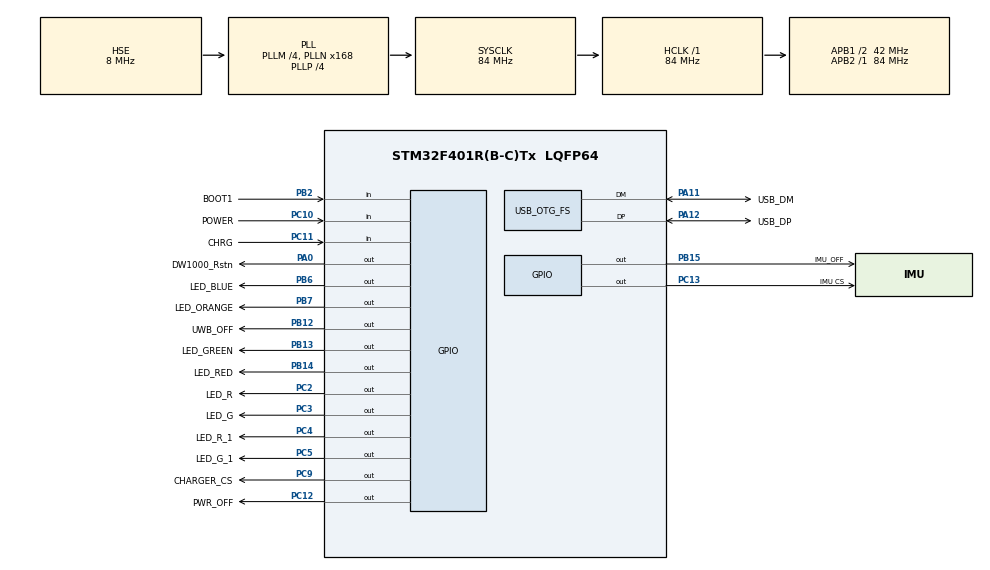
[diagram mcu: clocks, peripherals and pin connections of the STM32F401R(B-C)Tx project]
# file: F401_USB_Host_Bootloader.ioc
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Mcu.Family=STM32F4
Mcu.Name=STM32F401R(B-C)Tx
Mcu.Package=LQFP64
NVIC.OTG_FS_IRQn=true\:0\:0\:false\:false\:true\:false
NVIC.PriorityGroup=NVIC_PRIORITYGROUP_4
PA0-WKUP.GPIO_Label=DW1000_Rstn
PA0-WKUP.GPIO_Speed=GPIO_SPEED_FREQ_MEDIUM
PA0-WKUP.Signal=GPIO_Output
PA11.GPIO_Label=USB_DM
PA11.Mode=Host_Only
PA11.Signal=USB_OTG_FS_DM
PA12.GPIO_Label=USB_DP
PA12.Mode=Host_Only
PA12.Signal=USB_OTG_FS_DP
PA13.Mode=JTAG_5_pins
PA13.Signal=SYS_JTMS-SWDIO
PA14.Mode=JTAG_5_pins
PA14.Signal=SYS_JTCK-SWCLK
PA15.Mode=JTAG_5_pins
PA15.Signal=SYS_JTDI
PB12.GPIO_Label=UWB_OFF
PB12.GPIO_Speed=GPIO_SPEED_FREQ_MEDIUM
PB12.Signal=GPIO_Output
PB13.GPIO_Label=LED_GREEN
PB13.GPIO_Speed=GPIO_SPEED_FREQ_MEDIUM
PB13.Signal=GPIO_Output
PB14.GPIO_Label=LED_RED
PB14.GPIO_Speed=GPIO_SPEED_FREQ_MEDIUM
PB14.Signal=GPIO_Output
PB15.GPIO_Label=IMU_OFF
PB15.GPIO_Speed=GPIO_SPEED_FREQ_MEDIUM
PB15.Signal=GPIO_Output
PB2.GPIO_Label=BOOT1
PB2.Signal=GPIO_Input
PB3.Mode=JTAG_5_pins
PB3.Signal=SYS_JTDO-SWO
PB4.Mode=JTAG_5_pins
PB4.Signal=SYS_JTRST
PB6.GPIO_Label=LED_BLUE
PB6.GPIO_Speed=GPIO_SPEED_FREQ_MEDIUM
PB6.Signal=GPIO_Output
PB7.GPIO_Label=LED_ORANGE
PB7.GPIO_Speed=GPIO_SPEED_FREQ_MEDIUM
PB7.Signal=GPIO_Output
PC10.GPIO_Label=POWER
PC10.Signal=GPIO_Input
PC11.GPIO_Label=CHRG
PC11.Signal=GPIO_Input
PC12.GPIO_Label=PWR_OFF
PC12.GPIO_Speed=GPIO_SPEED_FREQ_MEDIUM
PC12.Signal=GPIO_Output
PC13-ANTI_TAMP.GPIO_Label=IMU CS
PC13-ANTI_TAMP.GPIO_Speed=GPIO_SPEED_FREQ_LOW
PC13-ANTI_TAMP.Signal=GPIO_Output
PC14-OSC32_IN.GPIO_Label=OSC32_IN
PC14-OSC32_IN.Mode=LSE-External-Oscillator
PC14-OSC32_IN.Signal=RCC_OSC32_IN
PC15-OSC32_OUT.GPIO_Label=OSC32_OUT
PC15-OSC32_OUT.Mode=LSE-External-Oscillator
PC15-OSC32_OUT.Signal=RCC_OSC32_OUT
PC2.GPIO_Label=LED_R
PC2.GPIO_Speed=GPIO_SPEED_FREQ_MEDIUM
PC2.Signal=GPIO_Output
PC3.GPIO_Label=LED_G
PC3.GPIO_Speed=GPIO_SPEED_FREQ_MEDIUM
PC3.Signal=GPIO_Output
PC4.GPIO_Label=LED_R_1
PC4.GPIO_Speed=GPIO_SPEED_FREQ_MEDIUM
PC4.Signal=GPIO_Output
PC5.GPIO_Label=LED_G_1
PC5.GPIO_Speed=GPIO_SPEED_FREQ_MEDIUM
PC5.Signal=GPIO_Output
PC9.GPIO_Label=CHARGER_CS
PC9.GPIO_Speed=GPIO_SPEED_FREQ_MEDIUM
PC9.Signal=GPIO_Output
PH0\ -\ OSC_IN.GPIO_Label=OSC_IN
PH0\ -\ OSC_IN.Mode=HSE-External-Oscillator
PH0\ -\ OSC_IN.Signal=RCC_OSC_IN
PH1\ -\ OSC_OUT.GPIO_Label=OSC_OUT
PH1\ -\ OSC_OUT.Mode=HSE-External-Oscillator
PH1\ -\ OSC_OUT.Signal=RCC_OSC_OUT
ProjectManager.HeapSize=0x1000
ProjectManager.StackSize=0x1000
ProjectManager.TargetToolchain=MDK-ARM V5
RCC.48MHZClocksFreq_Value=48000000
RCC.AHBFreq_Value=84000000
RCC.APB1CLKDivider=RCC_HCLK_DIV2
RCC.APB1Freq_Value=42000000
RCC.APB1TimFreq_Value=84000000
RCC.APB2Freq_Value=84000000
RCC.APB2TimFreq_Value=84000000
RCC.CortexFreq_Value=84000000
RCC.HCLKFreq_Value=84000000
RCC.HSE_VALUE=8000000
RCC.HSI_VALUE=16000000
RCC.PLLM=4
RCC.PLLN=168
RCC.PLLP=RCC_PLLP_DIV4
RCC.PLLQ=7
RCC.SYSCLKFreq_VALUE=84000000
RCC.SYSCLKSource=RCC_SYSCLKSOURCE_PLLCLK
RCC.VCOOutputFreq_Value=336000000
USB_HOST.USBH_HandleTypeDef=hUsbHostFS
USB_HOST.VirtualModeFS=Msc
USB_OTG_FS.VirtualMode=Host_Only
USB_OTG_FS.phy_itface=HCD_PHY_EMBEDDED
VP_FATFS_VS_USB.Mode=USB
VP_USB_HOST_VS_USB_HOST_MSC_FS.Mode=MSC_FS
board=F401_USB_Host_Bootloader

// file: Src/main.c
/**
  ******************************************************************************
  * @file           : main.c
  * @brief          : Main program body
  ******************************************************************************
  * This notice applies to any and all portions of this file
  * that are not between comment pairs USER CODE BEGIN and
  * USER CODE END. Other portions of this file, whether
  * inserted by the user or by software development tools
  * are owned by their respective copyright owners.
  *
  * Copyright (c) 2018 STMicroelectronics International N.V.
  * All rights reserved.
  *
  * Redistribution and use in source and binary forms, with or without
  * modification, are permitted, provided that the following conditions are met:
  *
  * 1. Redistribution of source code must retain the above copyright notice,
  *    this list of conditions and the following disclaimer.
  * 2. Redistributions in binary form must reproduce the above copyright notice,
  *    this list of conditions and the following disclaimer in the documentation
  *    and/or other materials provided with the distribution.
  * 3. Neither the name of STMicroelectronics nor the names of other
  *    contributors to this software may be used to endorse or promote products
  *    derived from this software without specific written permission.
  * 4. This software, including modifications and/or derivative works of this
  *    software, must execute solely and exclusively on microcontroller or
  *    microprocessor devices manufactured by or for STMicroelectronics.
  * 5. Redistribution and use of this software other than as permitted under
  *    this license is void and will automatically terminate your rights under
  *    this license.
  *
  * THIS SOFTWARE IS PROVIDED BY STMICROELECTRONICS AND CONTRIBUTORS "AS IS"
  * AND ANY EXPRESS, IMPLIED OR STATUTORY WARRANTIES, INCLUDING, BUT NOT
  * LIMITED TO, THE IMPLIED WARRANTIES OF MERCHANTABILITY, FITNESS FOR A
  * PARTICULAR PURPOSE AND NON-INFRINGEMENT OF THIRD PARTY INTELLECTUAL PROPERTY
  * RIGHTS ARE DISCLAIMED TO THE FULLEST EXTENT PERMITTED BY LAW. IN NO EVENT
  * SHALL STMICROELECTRONICS OR CONTRIBUTORS BE LIABLE FOR ANY DIRECT, INDIRECT,
  * INCIDENTAL, SPECIAL, EXEMPLARY, OR CONSEQUENTIAL DAMAGES (INCLUDING, BUT NOT
  * LIMITED TO, PROCUREMENT OF SUBSTITUTE GOODS OR SERVICES; LOSS OF USE, DATA,
  * OR PROFITS; OR BUSINESS INTERRUPTION) HOWEVER CAUSED AND ON ANY THEORY OF
  * LIABILITY, WHETHER IN CONTRACT, STRICT LIABILITY, OR TORT (INCLUDING
  * NEGLIGENCE OR OTHERWISE) ARISING IN ANY WAY OUT OF THE USE OF THIS SOFTWARE,
  * EVEN IF ADVISED OF THE POSSIBILITY OF SUCH DAMAGE.
  *
  ******************************************************************************
  */
#include "main.h"
#include "stm32f4xx_hal.h"
#include "fatfs.h"
#include "usb_host.h"

/* USER CODE BEGIN Includes */

#include "driver.h"

/* USER CODE END Includes */

/* USER CODE BEGIN PV */
/* Private variables ---------------------------------------------------------*/

/* USER CODE END PV */

void SystemClock_Config(void);
static void MX_GPIO_Init(void);
void MX_USB_HOST_Process(void);

/* USER CODE BEGIN PFP */
/* Private function prototypes -----------------------------------------------*/

/* USER CODE END PFP */

int main(void)
{

    /* MCU Configuration----------------------------------------------------------*/

    /* Reset of all peripherals, Initializes the Flash interface and the Systick. */
    HAL_Init();

    /* Configure the system clock */
    SystemClock_Config();

    /* Initialize all configured peripherals */
    MX_GPIO_Init();
    MX_USB_HOST_Init();
    MX_FATFS_Init();
    /* USER CODE BEGIN 2 */

    MX_USB_HOST_Process();
    App_Init();

    /* USER CODE END 2 */

    /* Infinite loop */
    /* USER CODE BEGIN WHILE */
    while (1)
    {
        App_Process();

        /* USER CODE END WHILE */
        MX_USB_HOST_Process();

    }

}

void SystemClock_Config(void)
{

    RCC_OscInitTypeDef RCC_OscInitStruct;
    RCC_ClkInitTypeDef RCC_ClkInitStruct;

    /**Configure the main internal regulator output voltage
    */
    __HAL_RCC_PWR_CLK_ENABLE();

    __HAL_PWR_VOLTAGESCALING_CONFIG(PWR_REGULATOR_VOLTAGE_SCALE2);

    /**Initializes the CPU, AHB and APB busses clocks
    */
    RCC_OscInitStruct.OscillatorType = RCC_OSCILLATORTYPE_HSE;
    RCC_OscInitStruct.HSEState = RCC_HSE_ON;
    RCC_OscInitStruct.PLL.PLLState = RCC_PLL_ON;
    RCC_OscInitStruct.PLL.PLLSource = RCC_PLLSOURCE_HSE;
    RCC_OscInitStruct.PLL.PLLM = 4;
    RCC_OscInitStruct.PLL.PLLN = 168;
    RCC_OscInitStruct.PLL.PLLP = RCC_PLLP_DIV4;
    RCC_OscInitStruct.PLL.PLLQ = 7;
    if (HAL_RCC_OscConfig(&RCC_OscInitStruct) != HAL_OK)
    {
        _Error_Handler(__FILE__, __LINE__);
    }

    /**Initializes the CPU, AHB and APB busses clocks
    */
    RCC_ClkInitStruct.ClockType = RCC_CLOCKTYPE_HCLK|RCC_CLOCKTYPE_SYSCLK
                                  |RCC_CLOCKTYPE_PCLK1|RCC_CLOCKTYPE_PCLK2;
    RCC_ClkInitStruct.SYSCLKSource = RCC_SYSCLKSOURCE_PLLCLK;
    RCC_ClkInitStruct.AHBCLKDivider = RCC_SYSCLK_DIV1;
    RCC_ClkInitStruct.APB1CLKDivider = RCC_HCLK_DIV2;
    RCC_ClkInitStruct.APB2CLKDivider = RCC_HCLK_DIV1;

    if (HAL_RCC_ClockConfig(&RCC_ClkInitStruct, FLASH_LATENCY_2) != HAL_OK)
    {
        _Error_Handler(__FILE__, __LINE__);
    }

    /**Configure the Systick interrupt time
    */
    HAL_SYSTICK_Config(HAL_RCC_GetHCLKFreq()/1000);

    /**Configure the Systick
    */
    HAL_SYSTICK_CLKSourceConfig(SYSTICK_CLKSOURCE_HCLK);

    /* SysTick_IRQn interrupt configuration */
    HAL_NVIC_SetPriority(SysTick_IRQn, 0, 0);
}

/** Configure pins as
        * Analog
        * Input
        * Output
        * EVENT_OUT
        * EXTI
*/
static void MX_GPIO_Init(void)
{

    GPIO_InitTypeDef GPIO_InitStruct;

    /* GPIO Ports Clock Enable */
    __HAL_RCC_GPIOC_CLK_ENABLE();
    __HAL_RCC_GPIOH_CLK_ENABLE();
    __HAL_RCC_GPIOA_CLK_ENABLE();
    __HAL_RCC_GPIOB_CLK_ENABLE();

    /*Configure GPIO pin Output Level */
    HAL_GPIO_WritePin(GPIOC, IMU_CS_Pin|LED_R_Pin|LED_G_Pin|LED_R_1_Pin
                      |LED_G_1_Pin|CHARGER_CS_Pin|PWR_OFF_Pin, GPIO_PIN_RESET);

    /*Configure GPIO pin Output Level */
    HAL_GPIO_WritePin(DW1000_Rstn_GPIO_Port, DW1000_Rstn_Pin, GPIO_PIN_RESET);

    /*Configure GPIO pin Output Level */
    HAL_GPIO_WritePin(GPIOB, UWB_OFF_Pin|LED_GREEN_Pin|LED_RED_Pin|IMU_OFF_Pin
                      |LED_BLUE_Pin|LED_ORANGE_Pin, GPIO_PIN_RESET);

    /*Configure GPIO pin : IMU_CS_Pin */
    GPIO_InitStruct.Pin = IMU_CS_Pin;
    GPIO_InitStruct.Mode = GPIO_MODE_OUTPUT_PP;
    GPIO_InitStruct.Pull = GPIO_NOPULL;
    GPIO_InitStruct.Speed = GPIO_SPEED_FREQ_LOW;
    HAL_GPIO_Init(IMU_CS_GPIO_Port, &GPIO_InitStruct);

    /*Configure GPIO pins : LED_R_Pin LED_G_Pin LED_R_1_Pin LED_G_1_Pin
                             CHARGER_CS_Pin PWR_OFF_Pin */
    GPIO_InitStruct.Pin = LED_R_Pin|LED_G_Pin|LED_R_1_Pin|LED_G_1_Pin
                          |CHARGER_CS_Pin|PWR_OFF_Pin;
    GPIO_InitStruct.Mode = GPIO_MODE_OUTPUT_PP;
    GPIO_InitStruct.Pull = GPIO_NOPULL;
    GPIO_InitStruct.Speed = GPIO_SPEED_FREQ_MEDIUM;
    HAL_GPIO_Init(GPIOC, &GPIO_InitStruct);

    /*Configure GPIO pin : DW1000_Rstn_Pin */
    GPIO_InitStruct.Pin = DW1000_Rstn_Pin;
    GPIO_InitStruct.Mode = GPIO_MODE_OUTPUT_PP;
    GPIO_InitStruct.Pull = GPIO_NOPULL;
    GPIO_InitStruct.Speed = GPIO_SPEED_FREQ_MEDIUM;
    HAL_GPIO_Init(DW1000_Rstn_GPIO_Port, &GPIO_InitStruct);

    /*Configure GPIO pin : BOOT1_Pin */
    GPIO_InitStruct.Pin = BOOT1_Pin;
    GPIO_InitStruct.Mode = GPIO_MODE_INPUT;
    GPIO_InitStruct.Pull = GPIO_NOPULL;
    HAL_GPIO_Init(BOOT1_GPIO_Port, &GPIO_InitStruct);

    /*Configure GPIO pins : UWB_OFF_Pin LED_GREEN_Pin LED_RED_Pin IMU_OFF_Pin
                             LED_BLUE_Pin LED_ORANGE_Pin */
    GPIO_InitStruct.Pin = UWB_OFF_Pin|LED_GREEN_Pin|LED_RED_Pin|IMU_OFF_Pin
                          |LED_BLUE_Pin|LED_ORANGE_Pin;
    GPIO_InitStruct.Mode = GPIO_MODE_OUTPUT_PP;
    GPIO_InitStruct.Pull = GPIO_NOPULL;
    GPIO_InitStruct.Speed = GPIO_SPEED_FREQ_MEDIUM;
    HAL_GPIO_Init(GPIOB, &GPIO_InitStruct);

    /*Configure GPIO pins : POWER_Pin CHRG_Pin */
    GPIO_InitStruct.Pin = POWER_Pin|CHRG_Pin;
    GPIO_InitStruct.Mode = GPIO_MODE_INPUT;
    GPIO_InitStruct.Pull = GPIO_NOPULL;
    HAL_GPIO_Init(GPIOC, &GPIO_InitStruct);

}

void _Error_Handler(char *file, int line)
{
    while(1)
    {
    }
}

/************************ (C) COPYRIGHT STMicroelectronics *****END OF FILE****/
